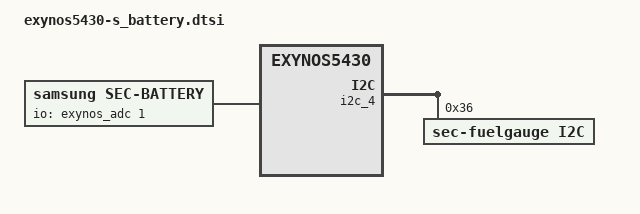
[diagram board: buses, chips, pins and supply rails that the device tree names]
/*
 * SAMSUNG UNIVERSAL5430 board device tree source
 *
 * Copyright (c) 2013 Samsung Electronics Co., Ltd.
 *		http://www.samsung.com
 *
 * This program is free software; you can redistribute it and/or modify
 * it under the terms of the GNU General Public License version 2 as
 * published by the Free Software Foundation.
*/

/ {
	i2c_4: i2c@14E80000 {
		compatible = "samsung,s3c2440-i2c";
		reg = <0x14E80000 0x1000>;
		interrupts = <0 443 0>;
		#address-cells = <1>;
		#size-cells = <0>;
		pinctrl-names = "default";
		pinctrl-0 = <&i2c4_bus>;
		clocks = <&clock 897>, <&clock 2447>;
		clock-names = "rate_i2c","gate_i2c";
		status = "okay";
		sec-fuelgauge@36 {
			compatible = "sec-fuelgauge,i2c";
			reg = <0x36>;
			pinctrl-names = "default";
			pinctrl-0 = <&fuel_irq>;
			fuelgauge,fuel_int = <&gpa1 5 0>;
			fuelgauge,fuel_alert_soc = <2>;
			fuelgauge,capacity_max = <990>;
			fuelgauge,capacity_max_margin = <30>;
			fuelgauge,capacity_min = <0>;
			fuelgauge,capacity_calculation_type = <28>;
			fuelgaguge,repeated_fuelalert;
			fuelgauge,rcomp0 = <0x5B>;
			fuelgauge,rcomp_charging = <0x6B>;
			fuelgauge,temp_cohot = <(-1400)>;
			fuelgauge,temp_cocold = <(-4700)>;
			fuelgauge,is_using_model_data;
			fuelgauge,type_str = "SDI";
		};
	};

	battery {
		status = "okay";
		compatible = "samsung,sec-battery";
		battery,vendor = "SDI SDI";
		battery,charger_name = "sec-charger";
		battery,fuelgauge_name = "sec-fuelgauge";
		battery,technology = <2>; /* POWER_SUPPLY_TECHNOLOGY_LION */

		battery,chip_vendor = "LSI";
		battery,temp_adc_type = <1>; /* SEC_BATTERY_ADC_TYPE_AP */

		battery,polling_time = <10 30 30 30 3600>;

		battery,temp_table_adc = <265 325 401 485 570 658 762 885 1041 1207
				         1364 1558 1777 2001 2226 2444 2645 2872 2899 2940
					 2981 3020 3085 3135 3183 3228 3270 3308 3458 3580 3685>;
		battery,temp_table_data = <900 850 800 750 700 650 600 550 500 450
					   400 350 300 250 200 150 100 50 40 30 20 10
					   0 (-10) (-20) (-30) (-40) (-50) (-100) (-150) (-200)>;

		battery,input_current_limit = <1450 0 0 1450 460 900 1000 460 1000 0 680 1900 1450 0 0 400 700 1300 300 1000 1600>;
		battery,fast_charging_current = <1390 0 0 1390 460 1200 1000 460 1200 0 900 1600 1390 0 0 400 700 1300 300 1000 1900>;
		battery,full_check_current_1st = <150 0 0 150 150 150 150 150 150 0 150 150 150 0 0 150 150 150 150 150 150>;
		battery,full_check_current_2nd = <2400 0 0 2400 2400 2400 2400 2400 2400 0 2400 2400 2400 0 0 2400 2400 2400 2400 2400 2400>;

		battery,adc_check_count = <5>;

		battery,cable_check_type = <4>; /* SEC_BATTERY_CABLE_CHECK_PSY */
		battery,cable_source_type = <1>; /* SEC_BATTERY_CABLE_SOURCE_EXTERNAL */
		battery,event_waiting_time = <600>;
		battery,polling_type = <1>; /* SEC_BATTERY_MONITOR_ALARM */
		battery,monitor_initial_count = <0>;

		battery,battery_check_type = <5>; /* SEC_BATTERY_CHECK_CHARGER */
		battery,check_count = <0>;
		battery,check_adc_max = <1440>;
		battery,check_adc_min = <0>;

		battery,ovp_uvlo_check_type = <3>; /* SEC_BATTERY_OVP_UVLO_CHGPOLLING */

		battery,thermal_source = <2>; /* SEC_BATTERY_THERMAL_SOURCE_ADC */

		battery,temp_check_type = <2>; /* _BATTERY_TEMP_CHECK_TEMP */
		battery,temp_check_count = <1>;
		battery,temp_highlimit_threshold_event = <800>;
		battery,temp_highlimit_recovery_event = <750>;
		battery,temp_high_threshold_event = <700>;
		battery,temp_high_recovery_event = <460>;
		battery,temp_low_threshold_event = <(-30)>;
		battery,temp_low_recovery_event = <0>;
		battery,temp_highlimit_threshold_normal = <800>;
		battery,temp_highlimit_recovery_normal = <750>;
		battery,temp_high_threshold_normal = <600>;
		battery,temp_high_recovery_normal = <460>;
		battery,temp_low_threshold_normal = <(-50)>;
		battery,temp_low_recovery_normal = <0>;
		battery,temp_highlimit_threshold_lpm = <800>;
		battery,temp_highlimit_recovery_lpm = <750>;
		battery,temp_high_threshold_lpm = <600>;
		battery,temp_high_recovery_lpm = <460>;
		battery,temp_low_threshold_lpm = <(-50)>;
		battery,temp_low_recovery_lpm = <0>;
		battery,full_check_type = <7>; /* SEC_BATTERY_FULLCHARGED_CHGPSY */
		battery,full_check_type_2nd = <3>; /* SEC_BATTERY_FULLCHARGED_TIME */
		battery,full_check_count = <1>;
		battery,chg_gpio_full_check = <0>;
		battery,chg_polarity_full_check = <1>;

		/* SEC_BATTERY_FULL_CONDITION_SOC |
		   SEC_BATTERY_FULL_CONDITION_NOTIMEFULL |
		   SEC_BATTERY_FULL_CONDITION_VCELL */
		battery,full_condition_type = <13>;
		battery,full_condition_soc = <97>;
		battery,full_condition_vcell = <4350>;

		battery,recharge_check_count = <2>;
		battery,recharge_condition_type = <4>; /* SEC_BATTERY_RECHARGE_CONDITION_VCELL */
		battery,recharge_condition_soc = <98>;
		battery,recharge_condition_vcell = <4350>;

		battery,charging_total_time = <21600>;
		battery,recharging_total_time = <5400>;
		battery,charging_reset_time = <0>;

		io-channels = <&exynos_adc 1>;
		io-channel-names = "adc-temp";
		#io-channel-cells = <1>;
		io-channel-ranges;
	};

	charger {
		status = "disable";
                /* Charger */
                battery,charger_name = "sec-charger";
                battery,wc_int = <&gpa3 5 0>;
                battery,wc_detect_gpio;
                battery,chg_gpio_en = <0>;
                battery,chg_polarity_en = <0>;
                battery,chg_gpio_status = <0>;
                battery,chg_polarity_status = <0>;
                battery,chg_float_voltage = <4400>;
	};
};
